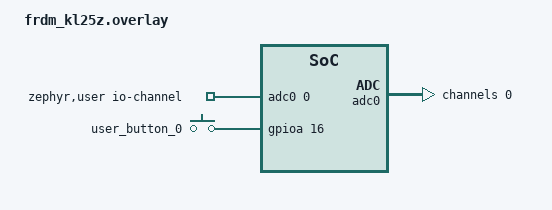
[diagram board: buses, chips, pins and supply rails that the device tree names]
#include <zephyr/dt-bindings/adc/adc.h>
#include <zephyr/dt-bindings/gpio/gpio.h>

/ {
    zephyr,user {
        io-channels = <&adc0 0>;
    };

    gpio_keys {
        compatible = "gpio-keys";

        user_button_0: button_0 {
            gpios = <&gpioa 16 GPIO_PULL_UP>;
        };
    };
};

&adc0 {
    #address-cells = <1>;
    #size-cells = <0>;

    channel@0 {
        reg = <0>;
        zephyr,gain = "ADC_GAIN_1";
        zephyr,reference = "ADC_REF_INTERNAL";
        zephyr,acquisition-time = <ADC_ACQ_TIME_DEFAULT>;
        zephyr,resolution = <12>;
    };
};


